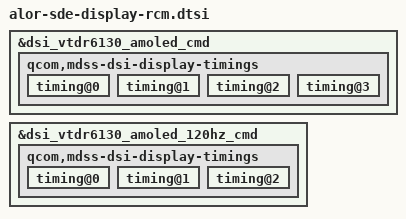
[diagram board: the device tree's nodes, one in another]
// SPDX-License-Identifier: BSD-3-Clause
/*
 * Copyright (c) Qualcomm Technologies, Inc. and/or its subsidiaries.
 */


#include "alor-sde-display-cdp.dtsi"

&dsi_vtdr6130_amoled_cmd {
	qcom,mdss-dsi-display-timings {
		timing@0 {
			/delete-property/ qcom,mdss-dsi-panel-clockrate;
		};

		timing@1 {
			/delete-property/ qcom,mdss-dsi-panel-clockrate;
		};

		timing@2 {
			/delete-property/ qcom,mdss-dsi-panel-clockrate;
		};

		timing@3 {
			/delete-property/ qcom,mdss-dsi-panel-clockrate;
		};
	};
};

&dsi_vtdr6130_amoled_120hz_cmd {
	qcom,mdss-dsi-display-timings {
		timing@0 {
			/delete-property/ qcom,mdss-dsi-panel-clockrate;
		};

		timing@1 {
			/delete-property/ qcom,mdss-dsi-panel-clockrate;
		};

		timing@2 {
			/delete-property/ qcom,mdss-dsi-panel-clockrate;
		};
	};
};
